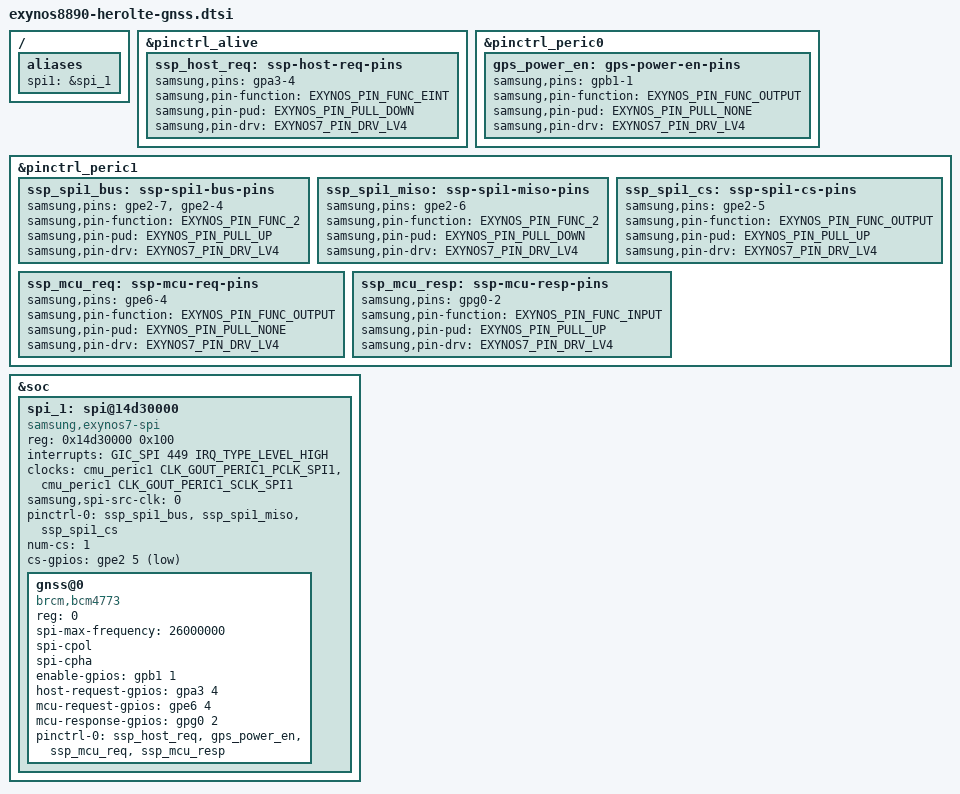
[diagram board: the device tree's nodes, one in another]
// SPDX-License-Identifier: GPL-2.0 OR BSD-3-Clause
/*
 * Samsung Galaxy S7 (herolte) BCM4773 GNSS transport bring-up.
 *
 * BCM4773 also hosts Samsung's SSP sensor path. This file intentionally only
 * wires the shared SPI/SSI transport and GNSS power GPIO; BBD sensor RPC
 * demultiplexing is left for follow-up work.
 */

#include <dt-bindings/gpio/gpio.h>
#include <dt-bindings/interrupt-controller/arm-gic.h>
#include <dt-bindings/interrupt-controller/irq.h>

/ {
	aliases {
		spi1 = &spi_1;
	};
};

&pinctrl_alive {
	ssp_host_req: ssp-host-req-pins {
		samsung,pins = "gpa3-4";
		samsung,pin-function = <EXYNOS_PIN_FUNC_EINT>;
		samsung,pin-pud = <EXYNOS_PIN_PULL_DOWN>;
		samsung,pin-drv = <EXYNOS7_PIN_DRV_LV4>;
	};
};

&pinctrl_peric0 {
	gps_power_en: gps-power-en-pins {
		samsung,pins = "gpb1-1";
		samsung,pin-function = <EXYNOS_PIN_FUNC_OUTPUT>;
		samsung,pin-pud = <EXYNOS_PIN_PULL_NONE>;
		samsung,pin-drv = <EXYNOS7_PIN_DRV_LV4>;
	};
};

&pinctrl_peric1 {
	/* Match Samsung's herolte electrical configuration for the SSP bus. */
	ssp_spi1_bus: ssp-spi1-bus-pins {
		samsung,pins = "gpe2-7", "gpe2-4";
		samsung,pin-function = <EXYNOS_PIN_FUNC_2>;
		samsung,pin-pud = <EXYNOS_PIN_PULL_UP>;
		samsung,pin-drv = <EXYNOS7_PIN_DRV_LV4>;
	};

	ssp_spi1_miso: ssp-spi1-miso-pins {
		samsung,pins = "gpe2-6";
		samsung,pin-function = <EXYNOS_PIN_FUNC_2>;
		samsung,pin-pud = <EXYNOS_PIN_PULL_DOWN>;
		samsung,pin-drv = <EXYNOS7_PIN_DRV_LV4>;
	};

	ssp_spi1_cs: ssp-spi1-cs-pins {
		samsung,pins = "gpe2-5";
		samsung,pin-function = <EXYNOS_PIN_FUNC_OUTPUT>;
		samsung,pin-pud = <EXYNOS_PIN_PULL_UP>;
		samsung,pin-drv = <EXYNOS7_PIN_DRV_LV4>;
	};

	ssp_mcu_req: ssp-mcu-req-pins {
		samsung,pins = "gpe6-4";
		samsung,pin-function = <EXYNOS_PIN_FUNC_OUTPUT>;
		samsung,pin-pud = <EXYNOS_PIN_PULL_NONE>;
		samsung,pin-drv = <EXYNOS7_PIN_DRV_LV4>;
	};

	ssp_mcu_resp: ssp-mcu-resp-pins {
		samsung,pins = "gpg0-2";
		samsung,pin-function = <EXYNOS_PIN_FUNC_INPUT>;
		samsung,pin-pud = <EXYNOS_PIN_PULL_UP>;
		samsung,pin-drv = <EXYNOS7_PIN_DRV_LV4>;
	};
};

&soc {
	spi_1: spi@14d30000 {
		compatible = "samsung,exynos7-spi";
		reg = <0x14d30000 0x100>;
		interrupts = <GIC_SPI 449 IRQ_TYPE_LEVEL_HIGH>;

		clocks = <&cmu_peric1 CLK_GOUT_PERIC1_PCLK_SPI1>,
			 <&cmu_peric1 CLK_GOUT_PERIC1_SCLK_SPI1>;
		clock-names = "spi", "spi_busclk0";
		samsung,spi-src-clk = <0>;

		pinctrl-0 = <&ssp_spi1_bus &ssp_spi1_miso &ssp_spi1_cs>;
		pinctrl-names = "default";

		#address-cells = <1>;
		#size-cells = <0>;
		num-cs = <1>;
		cs-gpios = <&gpe2 5 GPIO_ACTIVE_LOW>;

		status = "okay";

		gnss@0 {
			compatible = "brcm,bcm4773";
			reg = <0>;
			spi-max-frequency = <26000000>;
			spi-cpol;
			spi-cpha;

			enable-gpios = <&gpb1 1 GPIO_ACTIVE_HIGH>;
			host-request-gpios = <&gpa3 4 GPIO_ACTIVE_HIGH>;
			mcu-request-gpios = <&gpe6 4 GPIO_ACTIVE_HIGH>;
			mcu-response-gpios = <&gpg0 2 GPIO_ACTIVE_HIGH>;

			pinctrl-0 = <&ssp_host_req &gps_power_en
				     &ssp_mcu_req &ssp_mcu_resp>;
			pinctrl-names = "default";
		};
	};
};
